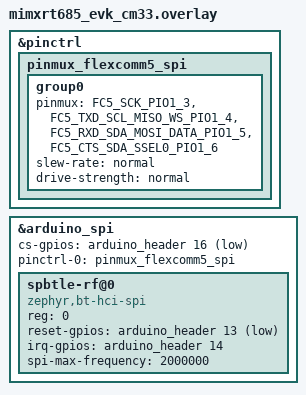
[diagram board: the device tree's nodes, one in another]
&pinctrl {
    pinmux_flexcomm5_spi: pinmux_flexcomm5_spi {
        group0 {
            pinmux = <FC5_SCK_PIO1_3>,
                     <FC5_TXD_SCL_MISO_WS_PIO1_4>,
                     <FC5_RXD_SDA_MOSI_DATA_PIO1_5>,
                     <FC5_CTS_SDA_SSEL0_PIO1_6>;
            slew-rate = "normal";
            drive-strength = "normal";
        };
    };
};

&arduino_spi {
    cs-gpios = <&arduino_header 16 (GPIO_ACTIVE_LOW)>;          /* D10 == FC5_CTS_SDA_SSEL0_PIO1_6 above */
    pinctrl-0 = <&pinmux_flexcomm5_spi>;
    //pre-delay = <1000>;
    //post-delay = <1000>;
    //frame-delay = <1000>;
    //transfer-delay = <1000>;

    // /delete-property/ dmas;
    // /delete-property/ dma-names;

    spbtle-rf@0 {
        compatible = "zephyr,bt-hci-spi";
        reg = <0>;
        reset-gpios = <&arduino_header 13 (GPIO_ACTIVE_LOW | GPIO_PULL_UP)>; /* D7 */
        //reset-assert-duration-ms = <500>;
        irq-gpios = <&arduino_header 14 (GPIO_ACTIVE_HIGH)>;  /* D8 */
        spi-max-frequency = <2000000>;
    };
};
